# STM32F730 register map
File version: 1.5
CPU: CM7 r0p1, little endian, MPU, FPU, 4 interrupt priority bits
Registers are 32-bit, read-write, reset 0x0 unless marked. A register's access mark holds for its fields unless they carry their own. Offsets are from the block's base; [hi:lo] are bit positions; lines under a group give offsets from that group; {n}, {i} and the like mark numbered series.

## RNG — Random number generator
Base 0x50060800
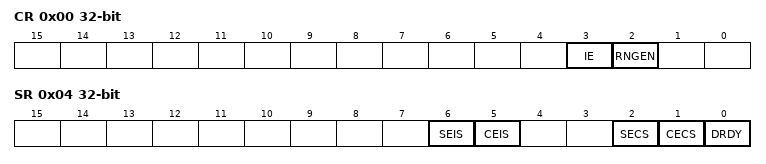
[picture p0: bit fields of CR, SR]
0x00 CR — control register
  [3] IE — Interrupt enable
    0=Disabled (RNG interrupt is disabled); 1=Enabled (RNG interrupt is enabled)
  [2] RNGEN — Random number generator enable
    0=Disabled (Random number generator is disabled); 1=Enabled (Random number generator is enabled)
0x04 SR access per field — status register
  [6] SEIS rw write-0-clears — Seed error interrupt status
    on write: 0=Clear flag | on read: 0=No faulty sequence detected; 1=Fault (At least one faulty sequence has been detected. See **SECS** bit description for details. An interrupt is pending if IE = 1 in the RNG_CR register.)
  [5] CEIS rw write-0-clears — Clock error interrupt status
    on write: 0=Clear flag | on read: 0=Correct (The RNG clock is correct); 1=Slow (The RNG has been detected too slow An interrupt is pending if IE = 1 in the RNG_CR register)
  [2] SECS ro — Seed error current status
    0=No faulty sequence has currently been detected. If the SEIS bit is set, this means that a faulty sequence was detected and the situation has been recovered.; 1=Fault (At least one faulty sequence has been detected - see ref manual for details)
  [1] CECS ro — Clock error current status
    0=Correct (The RNG clock is correct. If the CEIS bit is set, this means that a slow clock was detected and the situation has been recovered.); 1=Slow (The RNG clock is too slow)
  [0] DRDY ro — Data ready
    0=Invalid (The RNG_DR register is not yet valid, no random data is available); 1=Valid (The RNG_DR register contains valid random data. Once the RNG_DR register has been read, this bit returns to 0 until a new random value is generated.)
0x08 DR ro — data register
  [31:0] RNDATA — Random data

## SYSCFG — System configuration controller
Base 0x40013800
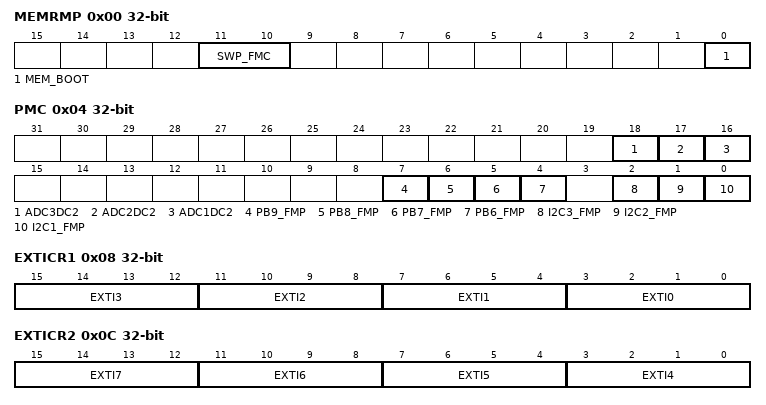
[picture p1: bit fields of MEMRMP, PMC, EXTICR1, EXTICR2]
0x00 MEMRMP — memory remap register
  [11:10] SWP_FMC — FMC memory mapping swap
  [0] MEM_BOOT — Memory boot mapping
0x04 PMC — peripheral mode configuration register
  [18] ADC3DC2
  [17] ADC2DC2
  [16] ADC1DC2 — ADC3DC2
  [7] PB9_FMP — Fast Mode + Enable
  [6] PB8_FMP — PB8_FMP Fast Mode + Enable
  [5] PB7_FMP — PB7_FMP Fast Mode + Enable
  [4] PB6_FMP — PB6_FMP Fast Mode
  [2] I2C3_FMP — I2C3_FMP I2C3 Fast Mode + Enable
  [1] I2C2_FMP — I2C2_FMP I2C2 Fast Mode + Enable
  [0] I2C1_FMP — I2C1_FMP I2C1 Fast Mode + Enable
0x08 EXTICR1 — external interrupt configuration register 1
  [4n+3:4n] EXTI{n} (n=0..3) — EXTI x configuration (x = 0 to 3)
0x0C EXTICR2 — external interrupt configuration register 2
  [4n-13:4n-16] EXTI{n} (n=4..7) — EXTI x configuration (x = 4 to 7)
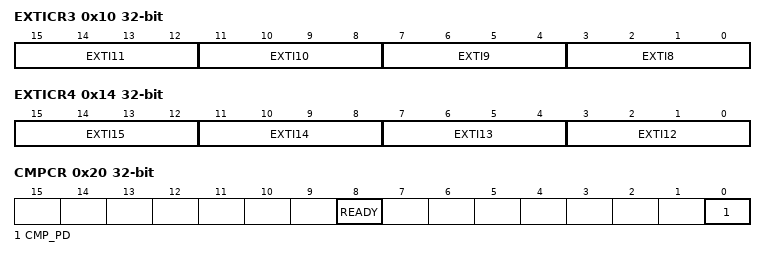
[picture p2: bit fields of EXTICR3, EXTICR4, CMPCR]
0x10 EXTICR3 — external interrupt configuration register 3
  [15:12] EXTI11 — EXTI x configuration (x = 8 to 11)
  [11:8] EXTI10
  [7:4] EXTI9 — EXTI x configuration (x = 8 to 11)
  [3:0] EXTI8 — EXTI x configuration (x = 8 to 11)
0x14 EXTICR4 — external interrupt configuration register 4
  [4n-45:4n-48] EXTI{n} (n=12..15) — EXTI x configuration (x = 12 to 15)
0x20 CMPCR ro — Compensation cell control register
  [8] READY
  [0] CMP_PD — Compensation cell power-down

## OTG_FS_HOST — USB on the go full speed
Base 0x50000400
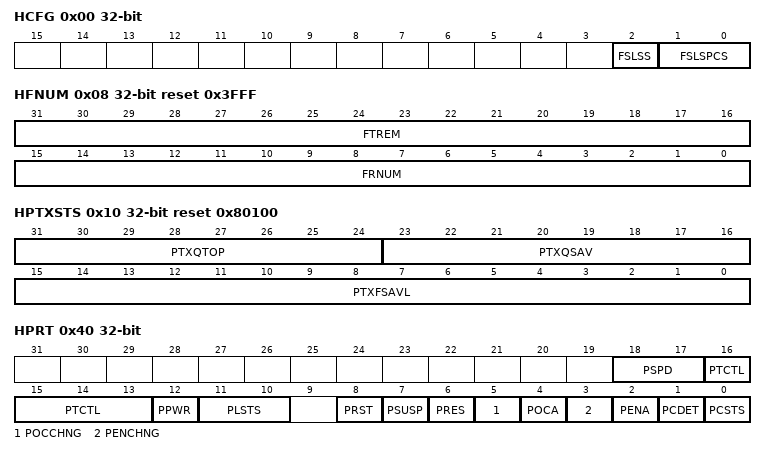
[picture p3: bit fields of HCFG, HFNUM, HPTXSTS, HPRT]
0x00 HCFG — OTG_FS host configuration register (OTG_FS_HCFG)
  [2] FSLSS — FS- and LS-only support
  [1:0] FSLSPCS — FS/LS PHY clock select
0x04 HFIR reset 0xEA60 — OTG_FS Host frame interval register
  [15:0] FRIVL — Frame interval
0x08 HFNUM ro reset 0x3FFF — OTG_FS host frame number/frame time remaining register (OTG_FS_HFNUM)
  [31:16] FTREM — Frame time remaining
  [15:0] FRNUM — Frame number
0x10 HPTXSTS access per field reset 0x80100 — OTG_FS_Host periodic transmit FIFO/queue status register (OTG_FS_HPTXSTS)
  [31:24] PTXQTOP ro — Top of the periodic transmit request queue
  [23:16] PTXQSAV ro — Periodic transmit request queue space available
  [15:0] PTXFSAVL rw — Periodic transmit data FIFO space available
0x14 HAINT ro — OTG_FS Host all channels interrupt register
  [15:0] HAINT — Channel interrupts
0x18 HAINTMSK — OTG_FS host all channels interrupt mask register
  [15:0] HAINTM — Channel interrupt mask
0x40 HPRT access per field — OTG_FS host port control and status register (OTG_FS_HPRT)
  [18:17] PSPD ro — Port speed
  [16:13] PTCTL rw — Port test control
  [12] PPWR rw — Port power
  [11:10] PLSTS ro — Port line status
  [8] PRST rw — Port reset
  [7] PSUSP rw — Port suspend
  [6] PRES rw — Port resume
  [5] POCCHNG rw — Port overcurrent change
  [4] POCA ro — Port overcurrent active
  [3] PENCHNG rw — Port enable/disable change
  [2] PENA rw — Port enable
  [1] PCDET rw — Port connect detected
  [0] PCSTS ro — Port connect status
{0x100+0x20*i} HC{i} (i=0..11) group — Host channel
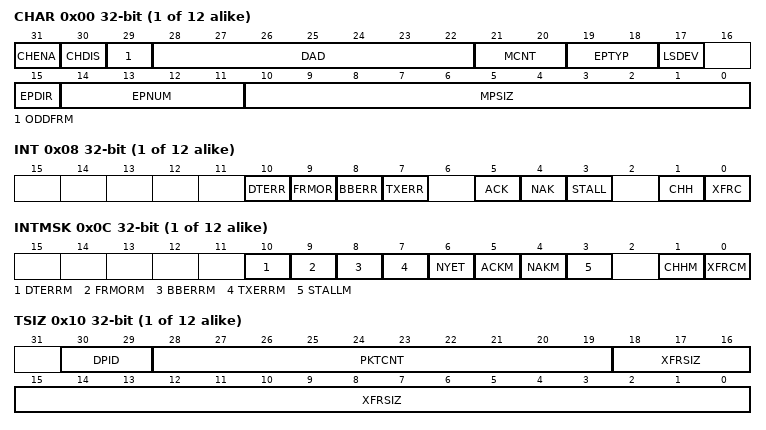
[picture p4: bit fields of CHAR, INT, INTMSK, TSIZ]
  0x00 CHAR — OTG_FS host channel-0 characteristics register (OTG_FS_HCCHAR0)
    [31] CHENA — Channel enable
    [30] CHDIS — Channel disable
    [29] ODDFRM — Odd frame
    [28:22] DAD — Device address
    [21:20] MCNT — Multicount
    [19:18] EPTYP — Endpoint type
    [17] LSDEV — Low-speed device
    [15] EPDIR — Endpoint direction
    [14:11] EPNUM — Endpoint number
    [10:0] MPSIZ — Maximum packet size
  0x08 INT — OTG_FS host channel-0 interrupt register (OTG_FS_HCINT0)
    [10] DTERR — Data toggle error
    [9] FRMOR — Frame overrun
    [8] BBERR — Babble error
    [7] TXERR — Transaction error
    [5] ACK — ACK response received/transmitted interrupt
    [4] NAK — NAK response received interrupt
    [3] STALL — STALL response received interrupt
    [1] CHH — Channel halted
    [0] XFRC — Transfer completed
  0x0C INTMSK — OTG_FS host channel-0 mask register (OTG_FS_HCINTMSK0)
    [10] DTERRM — Data toggle error mask
    [9] FRMORM — Frame overrun mask
    [8] BBERRM — Babble error mask
    [7] TXERRM — Transaction error mask
    [6] NYET — response received interrupt mask
    [5] ACKM — ACK response received/transmitted interrupt mask
    [4] NAKM — NAK response received interrupt mask
    [3] STALLM — STALL response received interrupt mask
    [1] CHHM — Channel halted mask
    [0] XFRCM — Transfer completed mask
  0x10 TSIZ — OTG_FS host channel-0 transfer size register
    [30:29] DPID — Data PID
    [28:19] PKTCNT — Packet count
    [18:0] XFRSIZ — Transfer size
